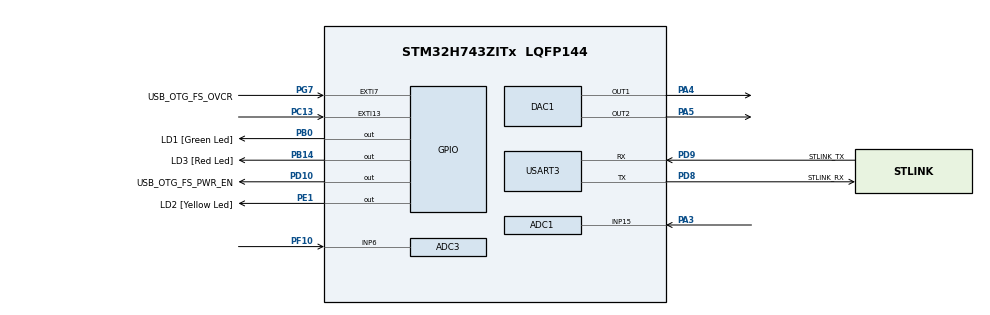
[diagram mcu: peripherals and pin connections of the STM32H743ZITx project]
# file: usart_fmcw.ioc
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ADC1.Channel-5\#ChannelRegularConversion=ADC_CHANNEL_15
ADC1.ConversionDataManagement=ADC_CONVERSIONDATA_DMA_CIRCULAR
ADC1.ExternalTrigConv=ADC_EXTERNALTRIG_T3_TRGO
ADC1.NbrOfConversionFlag=1
ADC1.OffsetNumber-5\#ChannelRegularConversion=ADC_OFFSET_NONE
ADC1.OffsetSignedSaturation-5\#ChannelRegularConversion=DISABLE
ADC1.Rank-5\#ChannelRegularConversion=1
ADC1.SamplingTime-5\#ChannelRegularConversion=ADC_SAMPLETIME_1CYCLE_5
ADC1.master=1
ADC3.Channel-2\#ChannelRegularConversion=ADC_CHANNEL_6
ADC3.ConversionDataManagement=ADC_CONVERSIONDATA_DMA_CIRCULAR
ADC3.ExternalTrigConv=ADC_EXTERNALTRIG_T3_TRGO
ADC3.NbrOfConversionFlag=1
ADC3.OffsetNumber-2\#ChannelRegularConversion=ADC_OFFSET_NONE
ADC3.OffsetSignedSaturation-2\#ChannelRegularConversion=DISABLE
ADC3.Rank-2\#ChannelRegularConversion=1
ADC3.SamplingTime-2\#ChannelRegularConversion=ADC_SAMPLETIME_1CYCLE_5
CORTEX_M7.AccessPermission-Cortex_Memory_Protection_Unit_Region0_Settings=MPU_REGION_FULL_ACCESS
CORTEX_M7.AccessPermission-Cortex_Memory_Protection_Unit_Region1_Settings=MPU_REGION_FULL_ACCESS
CORTEX_M7.BaseAddress-Cortex_Memory_Protection_Unit_Region0_Settings=0x30040000
CORTEX_M7.BaseAddress-Cortex_Memory_Protection_Unit_Region1_Settings=0x30044000
CORTEX_M7.CPU_DCache=Enabled
CORTEX_M7.CPU_ICache=Enabled
CORTEX_M7.Enable-Cortex_Memory_Protection_Unit_Region0_Settings=MPU_REGION_ENABLE
CORTEX_M7.Enable-Cortex_Memory_Protection_Unit_Region1_Settings=MPU_REGION_ENABLE
CORTEX_M7.IsBufferable-Cortex_Memory_Protection_Unit_Region0_Settings=MPU_ACCESS_BUFFERABLE
CORTEX_M7.IsShareable-Cortex_Memory_Protection_Unit_Region1_Settings=MPU_ACCESS_SHAREABLE
CORTEX_M7.MPU_Control=MPU_PRIVILEGED_DEFAULT
CORTEX_M7.Size-Cortex_Memory_Protection_Unit_Region0_Settings=MPU_REGION_SIZE_256B
CORTEX_M7.Size-Cortex_Memory_Protection_Unit_Region1_Settings=MPU_REGION_SIZE_16KB
CORTEX_M7.TypeExtField-Cortex_Memory_Protection_Unit_Region1_Settings=MPU_TEX_LEVEL1
DAC1.DAC_Channel-DAC_OUT1=DAC_CHANNEL_1
DAC1.DAC_Channel-DAC_OUT2=DAC_CHANNEL_2
DAC1.DAC_SampleAndHold-DAC_OUT1=DAC_SAMPLEANDHOLD_DISABLE
DAC1.DAC_Trigger-DAC_OUT1=DAC_TRIGGER_T8_TRGO
DAC1.DAC_Trigger-DAC_OUT2=DAC_TRIGGER_T4_TRGO
DAC1.DAC_UserTrimming-DAC_OUT1=DAC_TRIMMING_FACTORY
DAC1.WaveGeneration-DAC_OUT1=DISABLE
DAC1.WaveGeneration-DAC_OUT2=DISABLE
Dma.ADC1.0.Direction=DMA_PERIPH_TO_MEMORY
Dma.ADC1.0.EventEnable=DISABLE
Dma.ADC1.0.FIFOMode=DMA_FIFOMODE_DISABLE
Dma.ADC1.0.Instance=DMA1_Stream0
Dma.ADC1.0.MemDataAlignment=DMA_MDATAALIGN_HALFWORD
Dma.ADC1.0.MemInc=DMA_MINC_ENABLE
Dma.ADC1.0.Mode=DMA_CIRCULAR
Dma.ADC1.0.PeriphDataAlignment=DMA_PDATAALIGN_HALFWORD
Dma.ADC1.0.PeriphInc=DMA_PINC_DISABLE
Dma.ADC1.0.Polarity=HAL_DMAMUX_REQ_GEN_RISING
Dma.ADC1.0.Priority=DMA_PRIORITY_LOW
Dma.ADC1.0.RequestNumber=1
Dma.ADC1.0.SignalID=NONE
Dma.ADC1.0.SyncEnable=DISABLE
Dma.ADC1.0.SyncPolarity=HAL_DMAMUX_SYNC_NO_EVENT
Dma.ADC1.0.SyncRequestNumber=1
Dma.ADC1.0.SyncSignalID=NONE
Dma.ADC3.2.Direction=DMA_PERIPH_TO_MEMORY
Dma.ADC3.2.EventEnable=DISABLE
Dma.ADC3.2.FIFOMode=DMA_FIFOMODE_DISABLE
Dma.ADC3.2.Instance=DMA1_Stream1
Dma.ADC3.2.MemDataAlignment=DMA_MDATAALIGN_HALFWORD
Dma.ADC3.2.MemInc=DMA_MINC_ENABLE
Dma.ADC3.2.Mode=DMA_CIRCULAR
Dma.ADC3.2.PeriphDataAlignment=DMA_PDATAALIGN_HALFWORD
Dma.ADC3.2.PeriphInc=DMA_PINC_DISABLE
Dma.ADC3.2.Polarity=HAL_DMAMUX_REQ_GEN_RISING
Dma.ADC3.2.Priority=DMA_PRIORITY_LOW
Dma.ADC3.2.RequestNumber=1
Dma.ADC3.2.SignalID=NONE
Dma.ADC3.2.SyncEnable=DISABLE
Dma.ADC3.2.SyncPolarity=HAL_DMAMUX_SYNC_NO_EVENT
Dma.ADC3.2.SyncRequestNumber=1
Dma.ADC3.2.SyncSignalID=NONE
Dma.DAC1_CH1.3.Direction=DMA_MEMORY_TO_PERIPH
Dma.DAC1_CH1.3.EventEnable=DISABLE
Dma.DAC1_CH1.3.FIFOMode=DMA_FIFOMODE_DISABLE
Dma.DAC1_CH1.3.Instance=DMA1_Stream3
Dma.DAC1_CH1.3.MemDataAlignment=DMA_MDATAALIGN_HALFWORD
Dma.DAC1_CH1.3.MemInc=DMA_MINC_ENABLE
Dma.DAC1_CH1.3.Mode=DMA_CIRCULAR
Dma.DAC1_CH1.3.PeriphDataAlignment=DMA_PDATAALIGN_HALFWORD
Dma.DAC1_CH1.3.PeriphInc=DMA_PINC_DISABLE
Dma.DAC1_CH1.3.Polarity=HAL_DMAMUX_REQ_GEN_RISING
Dma.DAC1_CH1.3.Priority=DMA_PRIORITY_LOW
Dma.DAC1_CH1.3.RequestNumber=1
Dma.DAC1_CH1.3.SignalID=NONE
Dma.DAC1_CH1.3.SyncEnable=DISABLE
Dma.DAC1_CH1.3.SyncPolarity=HAL_DMAMUX_SYNC_NO_EVENT
Dma.DAC1_CH1.3.SyncRequestNumber=1
Dma.DAC1_CH1.3.SyncSignalID=NONE
Dma.DAC1_CH2.1.Direction=DMA_MEMORY_TO_PERIPH
Dma.DAC1_CH2.1.EventEnable=DISABLE
Dma.DAC1_CH2.1.FIFOMode=DMA_FIFOMODE_DISABLE
Dma.DAC1_CH2.1.Instance=DMA1_Stream2
Dma.DAC1_CH2.1.MemDataAlignment=DMA_MDATAALIGN_HALFWORD
Dma.DAC1_CH2.1.MemInc=DMA_MINC_ENABLE
Dma.DAC1_CH2.1.Mode=DMA_CIRCULAR
Dma.DAC1_CH2.1.PeriphDataAlignment=DMA_PDATAALIGN_HALFWORD
Dma.DAC1_CH2.1.PeriphInc=DMA_PINC_DISABLE
Dma.DAC1_CH2.1.Polarity=HAL_DMAMUX_REQ_GEN_RISING
Dma.DAC1_CH2.1.Priority=DMA_PRIORITY_LOW
Dma.DAC1_CH2.1.RequestNumber=1
Dma.DAC1_CH2.1.SignalID=NONE
Dma.DAC1_CH2.1.SyncEnable=DISABLE
Dma.DAC1_CH2.1.SyncPolarity=HAL_DMAMUX_SYNC_NO_EVENT
Dma.DAC1_CH2.1.SyncRequestNumber=1
Dma.DAC1_CH2.1.SyncSignalID=NONE
Dma.Request0=ADC1
Dma.Request1=DAC1_CH2
Dma.Request2=ADC3
Dma.Request3=DAC1_CH1
Mcu.Family=STM32H7
Mcu.Name=STM32H743ZITx
Mcu.Package=LQFP144
NVIC.DMA1_Stream0_IRQn=true\:8\:0\:true\:false\:true\:false\:true
NVIC.DMA1_Stream1_IRQn=true\:8\:0\:true\:false\:true\:false\:true
NVIC.DMA1_Stream2_IRQn=true\:0\:0\:false\:false\:true\:false\:true
NVIC.DMA1_Stream3_IRQn=true\:0\:0\:false\:false\:true\:false\:true
NVIC.EXTI15_10_IRQn=true\:0\:0\:false\:false\:true\:true\:true
NVIC.PriorityGroup=NVIC_PRIORITYGROUP_4
NVIC.TIM1_UP_IRQn=true\:0\:0\:false\:false\:true\:false\:true
NVIC.TIM2_IRQn=true\:0\:0\:false\:false\:true\:true\:true
NVIC.TimeBase=TIM1_UP_IRQn
NVIC.TimeBaseIP=TIM1
PA1.Signal=ETH_REF_CLK
PA11.Signal=USB_OTG_FS_DM
PA12.Signal=USB_OTG_FS_DP
PA2.Signal=ETH_MDIO
PA3.Signal=ADCx_INP15
PA4.Signal=COMP_DAC11_group
PA5.Signal=COMP_DAC12_group
PA7.Signal=ETH_CRS_DV
PA8.Signal=USB_OTG_FS_SOF
PA9.Signal=USB_OTG_FS_VBUS
PB0.GPIO_Label=LD1 [Green Led]
PB0.Signal=GPIO_Output
PB13.Signal=ETH_TXD1
PB14.GPIO_Label=LD3 [Red Led]
PB14.Signal=GPIO_Output
PC1.Signal=ETH_MDC
PC13.GPIO_ModeDefaultEXTI=GPIO_MODE_IT_RISING
PC13.Signal=GPXTI13
PC14-OSC32_IN\ (OSC32_IN).Mode=LSE-External-Oscillator
PC14-OSC32_IN\ (OSC32_IN).Signal=RCC_OSC32_IN
PC15-OSC32_OUT\ (OSC32_OUT).Mode=LSE-External-Oscillator
PC15-OSC32_OUT\ (OSC32_OUT).Signal=RCC_OSC32_OUT
PC4.Signal=ETH_RXD0
PC5.Signal=ETH_RXD1
PD10.GPIO_Label=USB_OTG_FS_PWR_EN
PD10.Signal=GPIO_Output
PD8.GPIO_Label=STLINK_RX
PD8.Mode=Asynchronous
PD8.Signal=USART3_TX
PD9.GPIO_Label=STLINK_TX
PD9.Mode=Asynchronous
PD9.Signal=USART3_RX
PE1.GPIO_Label=LD2 [Yellow Led]
PE1.Signal=GPIO_Output
PF10.Mode=IN6-Single-Ended
PF10.Signal=ADC3_INP6
PG11.Signal=ETH_TX_EN
PG13.Signal=ETH_TXD0
PG7.GPIO_Label=USB_OTG_FS_OVCR
PG7.Signal=GPXTI7
PH0-OSC_IN\ (PH0).Mode=HSE-External-Clock-Source
PH0-OSC_IN\ (PH0).Signal=RCC_OSC_IN
PH1-OSC_OUT\ (PH1).Signal=RCC_OSC_OUT
ProjectManager.HeapSize=0x200
ProjectManager.StackSize=0x400
ProjectManager.TargetToolchain=STM32CubeIDE
RCC.ADCFreq_Value=75000000
RCC.APB1Freq_Value=100000000
RCC.APB2Freq_Value=100000000
RCC.APB3Freq_Value=100000000
RCC.APB4Freq_Value=100000000
RCC.CortexFreq_Value=400000000
RCC.D1PPRE=RCC_APB3_DIV2
RCC.D2PPRE1=RCC_APB1_DIV2
RCC.D2PPRE2=RCC_APB2_DIV2
RCC.D3PPRE=RCC_APB4_DIV2
RCC.DIVM1=1
RCC.DIVM2=1
RCC.DIVN1=100
RCC.DIVN2=18
RCC.DIVN3=32
RCC.DIVQ1=4
RCC.HCLKFreq_Value=200000000
RCC.HPRE=RCC_HCLK_DIV2
RCC.HSE_VALUE=8000000
RCC.PLL2FRACN=6144
RCC.PLLFRACN=0
RCC.PLLSourceVirtual=RCC_PLLSOURCE_HSE
RCC.SYSCLKFreq_VALUE=400000000
RCC.SYSCLKSource=RCC_SYSCLKSOURCE_PLLCLK
RCC.USBCLockSelection=RCC_USBCLKSOURCE_HSI48
RCC.USBFreq_Value=48000000
SH.ADCx_INP15.0=ADC1_INP15,IN15-Single-Ended
SH.COMP_DAC11_group.0=DAC1_OUT1,DAC_OUT1
SH.COMP_DAC12_group.0=DAC1_OUT2,DAC_OUT2
TIM2.Period=200000
TIM2.TIM_MasterOutputTrigger=TIM_TRGO_UPDATE
TIM2.TIM_MasterSlaveMode=TIM_MASTERSLAVEMODE_ENABLE
TIM3.Period=3051
TIM3.TIM_MasterOutputTrigger=TIM_TRGO_UPDATE
TIM4.Period=6103
TIM4.TIM_MasterOutputTrigger=TIM_TRGO_UPDATE
TIM8.Period=24414
TIM8.TIM_MasterOutputTrigger=TIM_TRGO_UPDATE
USART3.VirtualMode-Asynchronous=VM_ASYNC
VP_SYS_VS_tim1.Mode=TIM1
VP_TIM2_VS_ClockSourceINT.Mode=Internal
VP_TIM3_VS_ClockSourceINT.Mode=Internal
VP_TIM4_VS_ClockSourceINT.Mode=Internal
VP_TIM8_VS_ClockSourceINT.Mode=Internal
board=NUCLEO-H743ZI2

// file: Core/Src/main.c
/* USER CODE BEGIN Header */
/**
  ******************************************************************************
  * @file           : main.c
  * @brief          : Main program body
  ******************************************************************************
  * @attention
  *
  * <h2><center>&copy; Copyright (c) 2021 STMicroelectronics.
  * All rights reserved.</center></h2>
  *
  * This software component is licensed by ST under Ultimate Liberty license
  * SLA0044, the "License"; You may not use this file except in compliance with
  * the License. You may obtain a copy of the License at:
  *                             www.st.com/SLA0044
  *
  ******************************************************************************
  */
/* USER CODE END Header */
#include "main.h"
#include "adc.h"
#include "dac.h"
#include "dma.h"
#include "tim.h"
#include "usart.h"
#include "gpio.h"

/* USER CODE BEGIN Includes */
#include "radar.h"
/* USER CODE END Includes */

void SystemClock_Config(void);
void PeriphCommonClock_Config(void);
static void MPU_Config(void);

int main(void)
{

  /* MPU Configuration--------------------------------------------------------*/

  MPU_Config();

  /* Enable I-Cache---------------------------------------------------------*/
  SCB_EnableICache();

  /* Enable D-Cache---------------------------------------------------------*/
  SCB_EnableDCache();

  /* MCU Configuration--------------------------------------------------------*/

  /* Reset of all peripherals, Initializes the Flash interface and the Systick. */
  HAL_Init();

  /* Configure the system clock */
  SystemClock_Config();

/* Configure the peripherals common clocks */
  PeriphCommonClock_Config();

  /* Initialize all configured peripherals */
  MX_GPIO_Init();
  MX_DMA_Init();
  MX_USART3_UART_Init();
  MX_ADC1_Init();
  MX_DAC1_Init();
  MX_TIM2_Init();
  MX_TIM3_Init();
  MX_TIM4_Init();
  MX_TIM8_Init();
  MX_ADC3_Init();
  /* USER CODE BEGIN 2 */

  HAL_Delay(1000);
  init_hardware();
  /* USER CODE END 2 */

  /* Infinite loop */
  while (1)
  {

    /* USER CODE BEGIN 3 */
	radar_routine();
  }
  /* USER CODE END 3 */
}

void SystemClock_Config(void)
{
  RCC_OscInitTypeDef RCC_OscInitStruct = {0};
  RCC_ClkInitTypeDef RCC_ClkInitStruct = {0};

  /** Supply configuration update enable
  */
  HAL_PWREx_ConfigSupply(PWR_LDO_SUPPLY);
  /** Configure the main internal regulator output voltage
  */
  __HAL_PWR_VOLTAGESCALING_CONFIG(PWR_REGULATOR_VOLTAGE_SCALE1);

  while(!__HAL_PWR_GET_FLAG(PWR_FLAG_VOSRDY)) {}
  /** Macro to configure the PLL clock source
  */
  __HAL_RCC_PLL_PLLSOURCE_CONFIG(RCC_PLLSOURCE_HSE);
  /** Initializes the RCC Oscillators according to the specified parameters
  * in the RCC_OscInitTypeDef structure.
  */
  RCC_OscInitStruct.OscillatorType = RCC_OSCILLATORTYPE_HSE;
  RCC_OscInitStruct.HSEState = RCC_HSE_BYPASS;
  RCC_OscInitStruct.PLL.PLLState = RCC_PLL_ON;
  RCC_OscInitStruct.PLL.PLLSource = RCC_PLLSOURCE_HSE;
  RCC_OscInitStruct.PLL.PLLM = 1;
  RCC_OscInitStruct.PLL.PLLN = 100;
  RCC_OscInitStruct.PLL.PLLP = 2;
  RCC_OscInitStruct.PLL.PLLQ = 4;
  RCC_OscInitStruct.PLL.PLLR = 2;
  RCC_OscInitStruct.PLL.PLLRGE = RCC_PLL1VCIRANGE_3;
  RCC_OscInitStruct.PLL.PLLVCOSEL = RCC_PLL1VCOWIDE;
  RCC_OscInitStruct.PLL.PLLFRACN = 0;
  if (HAL_RCC_OscConfig(&RCC_OscInitStruct) != HAL_OK)
  {
    Error_Handler();
  }
  /** Initializes the CPU, AHB and APB buses clocks
  */
  RCC_ClkInitStruct.ClockType = RCC_CLOCKTYPE_HCLK|RCC_CLOCKTYPE_SYSCLK
                              |RCC_CLOCKTYPE_PCLK1|RCC_CLOCKTYPE_PCLK2
                              |RCC_CLOCKTYPE_D3PCLK1|RCC_CLOCKTYPE_D1PCLK1;
  RCC_ClkInitStruct.SYSCLKSource = RCC_SYSCLKSOURCE_PLLCLK;
  RCC_ClkInitStruct.SYSCLKDivider = RCC_SYSCLK_DIV1;
  RCC_ClkInitStruct.AHBCLKDivider = RCC_HCLK_DIV2;
  RCC_ClkInitStruct.APB3CLKDivider = RCC_APB3_DIV2;
  RCC_ClkInitStruct.APB1CLKDivider = RCC_APB1_DIV2;
  RCC_ClkInitStruct.APB2CLKDivider = RCC_APB2_DIV2;
  RCC_ClkInitStruct.APB4CLKDivider = RCC_APB4_DIV2;

  if (HAL_RCC_ClockConfig(&RCC_ClkInitStruct, FLASH_LATENCY_2) != HAL_OK)
  {
    Error_Handler();
  }
}

void PeriphCommonClock_Config(void)
{
  RCC_PeriphCLKInitTypeDef PeriphClkInitStruct = {0};

  /** Initializes the peripherals clock
  */
  PeriphClkInitStruct.PeriphClockSelection = RCC_PERIPHCLK_ADC;
  PeriphClkInitStruct.PLL2.PLL2M = 1;
  PeriphClkInitStruct.PLL2.PLL2N = 18;
  PeriphClkInitStruct.PLL2.PLL2P = 2;
  PeriphClkInitStruct.PLL2.PLL2Q = 2;
  PeriphClkInitStruct.PLL2.PLL2R = 2;
  PeriphClkInitStruct.PLL2.PLL2RGE = RCC_PLL2VCIRANGE_3;
  PeriphClkInitStruct.PLL2.PLL2VCOSEL = RCC_PLL2VCOMEDIUM;
  PeriphClkInitStruct.PLL2.PLL2FRACN = 6144;
  PeriphClkInitStruct.AdcClockSelection = RCC_ADCCLKSOURCE_PLL2;
  if (HAL_RCCEx_PeriphCLKConfig(&PeriphClkInitStruct) != HAL_OK)
  {
    Error_Handler();
  }
}

/* MPU Configuration */

void MPU_Config(void)
{
  MPU_Region_InitTypeDef MPU_InitStruct = {0};

  /* Disables the MPU */
  HAL_MPU_Disable();
  /** Initializes and configures the Region and the memory to be protected
  */
  MPU_InitStruct.Enable = MPU_REGION_ENABLE;
  MPU_InitStruct.Number = MPU_REGION_NUMBER0;
  MPU_InitStruct.BaseAddress = 0x30040000;
  MPU_InitStruct.Size = MPU_REGION_SIZE_256B;
  MPU_InitStruct.SubRegionDisable = 0x0;
  MPU_InitStruct.TypeExtField = MPU_TEX_LEVEL0;
  MPU_InitStruct.AccessPermission = MPU_REGION_FULL_ACCESS;
  MPU_InitStruct.DisableExec = MPU_INSTRUCTION_ACCESS_ENABLE;
  MPU_InitStruct.IsShareable = MPU_ACCESS_NOT_SHAREABLE;
  MPU_InitStruct.IsCacheable = MPU_ACCESS_NOT_CACHEABLE;
  MPU_InitStruct.IsBufferable = MPU_ACCESS_BUFFERABLE;

  HAL_MPU_ConfigRegion(&MPU_InitStruct);
  /** Initializes and configures the Region and the memory to be protected
  */
  MPU_InitStruct.Number = MPU_REGION_NUMBER1;
  MPU_InitStruct.BaseAddress = 0x30044000;
  MPU_InitStruct.Size = MPU_REGION_SIZE_16KB;
  MPU_InitStruct.TypeExtField = MPU_TEX_LEVEL1;
  MPU_InitStruct.IsShareable = MPU_ACCESS_SHAREABLE;
  MPU_InitStruct.IsBufferable = MPU_ACCESS_NOT_BUFFERABLE;

  HAL_MPU_ConfigRegion(&MPU_InitStruct);
  /* Enables the MPU */
  HAL_MPU_Enable(MPU_PRIVILEGED_DEFAULT);

}
void HAL_TIM_PeriodElapsedCallback(TIM_HandleTypeDef *htim)
{
  if (htim->Instance == TIM1) {
    HAL_IncTick();
  }
  /* USER CODE BEGIN Callback 1 */

  if (htim->Instance == TIM2) {
	  _1ms_tick_acc++;
  }
  /* USER CODE END Callback 1 */
}

void Error_Handler(void)
{
  __disable_irq();
  while (1)
  {
  }
}

/************************ (C) COPYRIGHT STMicroelectronics *****END OF FILE****/
